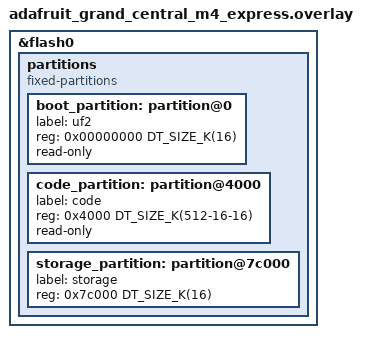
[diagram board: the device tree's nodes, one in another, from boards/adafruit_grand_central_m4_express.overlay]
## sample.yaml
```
sample:
  name: BACnet Smart Actuator (B-SA)

common:
  platform_allow:
    - nucleo_f429zi
    - rpi_pico
    - adafruit_grand_central_m4_express
  build_only: true

tests:

  bacnet-stack.sample.profile.b-sa.bacdl_none:
    tags: bacnet

  bacnet-stack.sample.profile.b-sa.bacdl_mstp:
    extra_configs:
      - CONFIG_BACDL_MSTP=y
    tags: introduction

  bacnet-stack.sample.profile.b-sa.bacdl_bip:
    extra_configs:
      - CONFIG_BACDL_BIP=y
    tags: introduction

  bacnet-stack.sample.profile.b-sa.bacdl_bip6:
    skip: true
    extra_configs:
      - CONFIG_BACDL_BIP6=y
    tags: introduction

  bacnet-stack.sample.profile.b-sa.bacdl_ethernet:
    skip: true
    extra_configs:
      - CONFIG_BACDL_ETHERNET=y
    tags: introduction
```

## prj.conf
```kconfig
# General config
#CONFIG_ASSERT=y
#CONFIG_ASSERT_LEVEL=2
#CONFIG_ASSERT_VERBOSE=y

# Compiler library config
#CONFIG_PICOLIBC=y
#CONFIG_PICOLIBC_USE_MODULE=y
#CONFIG_REQUIRES_FULL_LIBC=y
#CONFIG_MINIMAL_LIBC=y

# system
# some heap is needed for the shell
CONFIG_HEAP_MEM_POOL_SIZE=2048
CONFIG_KERNEL_MEM_POOL=y
CONFIG_MAIN_THREAD_PRIORITY=7
#CONFIG_PICOLIBC=y
CONFIG_ISR_STACK_SIZE=8192
CONFIG_MAIN_STACK_SIZE=8192
CONFIG_IDLE_STACK_SIZE=2048
CONFIG_INIT_STACKS=y

# BACnet Library
CONFIG_BACNETSTACK=y
# BACnet Library - shell
CONFIG_BACNETSTACK_BACNET_SHELL=y
CONFIG_BACNETSTACK_BACNET_BASIC_SHELL=y
CONFIG_BACAPP_PRINT_ENABLED=y
CONFIG_SHELL_STACK_SIZE=16384
# BACnet settings subsystem
CONFIG_BACNETSTACK_BACNET_SETTINGS=y
CONFIG_BACNET_SETTINGS_SHELL=y
# BACnet Library - options
CONFIG_BACNET_MAX_CHARACTER_STRING_BYTES=128
CONFIG_BACAPP_MINIMAL=y
CONFIG_BACAPP_HOST_N_PORT=y
# BACnet Library - objects
CONFIG_BACNET_BASIC_OBJECT_NETWORK_PORT=y
CONFIG_BACNET_BASIC_OBJECT_ANALOG_OUTPUT=y
# BACnet settings subsystem
#CONFIG_BACNETSTACK_BACNET_SETTINGS=y
#CONFIG_BACNET_SETTINGS=y
#CONFIG_BACNET_SETTINGS_SHELL=y
# BACnet Library - server framework
CONFIG_BACNET_BASIC_SERVER=y

# BACnet Datalink Options
CONFIG_BACDL_BIP=y
CONFIG_BACDL_BIP_PORT=47808
# don't define index if you want to use the default interface
# note: with DHCP and AutoIP enabled, index 0=AutoIP, 1=DHCP
# CONFIG_BACDL_BIP_ADDRESS_INDEX=1

# networking
CONFIG_NETWORKING=y
CONFIG_NET_L2_ETHERNET=y
#CONFIG_NET_ARP=y
#CONFIG_NET_TCP=y
CONFIG_NET_UDP=y
CONFIG_NET_SHELL=y
CONFIG_NET_SOCKETS=y
CONFIG_NET_IPV4=y
CONFIG_NET_IPV4_LOG_LEVEL_DBG=n
CONFIG_NET_IF_MAX_IPV4_COUNT=2
CONFIG_NET_IF_UNICAST_IPV4_ADDR_COUNT=2
CONFIG_NET_IF_MCAST_IPV4_ADDR_COUNT=2
# Dynamic IP address
CONFIG_NET_DHCPV4=y
CONFIG_NET_DHCPV4_LOG_LEVEL_DBG=n
CONFIG_NET_IPV4_AUTO=n
CONFIG_NET_IPV4_AUTO_LOG_LEVEL_DBG=n
CONFIG_NET_ICMPV4_LOG_LEVEL_DBG=n
# read the MAC address from settings and set via net_mgmt()
CONFIG_NET_MGMT_EVENT=y
CONFIG_NET_L2_ETHERNET_MGMT=y
CONFIG_NET_CONNECTION_MANAGER=y

# Network debug config
CONFIG_NET_LOG=y
CONFIG_NET_SHELL=y

#CONFIG_DNS_RESOLVER=y
#CONFIG_SLIP_STATISTICS=n

CONFIG_NET_TX_STACK_SIZE=8192
CONFIG_NET_RX_STACK_SIZE=8192

# Enable Shell, Console, and Logging features
CONFIG_CONSOLE=y
CONFIG_PRINTK=y
CONFIG_SHELL=y
CONFIG_KERNEL_SHELL=y
CONFIG_THREAD_MONITOR=y
#CONFIG_BOOT_BANNER=n
CONFIG_THREAD_NAME=y
CONFIG_DEVICE_SHELL=y
#CONFIG_POSIX_CLOCK=y
#CONFIG_DATE_SHELL=y
CONFIG_LOG=y
CONFIG_LOG_BACKEND_UART=y
CONFIG_SHELL_LOG_BACKEND=n
#CONFIG_LOG_STRDUP_BUF_COUNT=4
#CONFIG_LOG_STRDUP_MAX_STRING=96
#CONFIG_NET_CONN_LOG_LEVEL_DEFAULT=n
#CONFIG_NET_CONN_LOG_LEVEL_DBG=y
#CONFIG_NET_IF_LOG_LEVEL_DEFAULT=n
CONFIG_NET_IF_LOG_LEVEL_DBG=n
CONFIG_NET_LOG=y

# enable the thread, stack, and runtime stats
CONFIG_THREAD_ANALYZER=y
CONFIG_THREAD_STACK_INFO=y
CONFIG_THREAD_RUNTIME_STATS=y
#CONFIG_THREAD_RUNTIME_STATS_USE_TIMING_FUNCTIONS=n
#CONFIG_SCHED_THREAD_USAGE=y
#CONFIG_SCHED_THREAD_USAGE_ANALYSIS=y
CONFIG_STATS=y
CONFIG_STATS_SHELL=y

#
# Storage
#
# the dependencies of the SETTINGS option.
CONFIG_FLASH=y
CONFIG_FLASH_MAP=y
#CONFIG_FLASH_PAGE_LAYOUT=y
CONFIG_NVS=y
CONFIG_SETTINGS=y
CONFIG_SETTINGS_NVS=y
CONFIG_SETTINGS_RUNTIME=y
CONFIG_REBOOT=y
#CONFIG_SETTINGS_FILE=y
#CONFIG_SETTINGS_SHELL=y
# native_posix uses a simulated flash
#CONFIG_FLASH_SIMULATOR=y
#CONFIG_DISK_ACCESS=y.
#CONFIG_FILE_SYSTEM=y
#CONFIG_FILE_SYSTEM_LITTLEFS=y
#CONFIG_FILE_SYSTEM_SHELL=y

CONFIG_TEST_RANDOM_GENERATOR=y
CONFIG_TIMER_RANDOM_GENERATOR=y
```

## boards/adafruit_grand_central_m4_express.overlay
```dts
/*
 * Copyright (c) 2020 Google LLC.
 * Copyright (c) 2024 Daikin Comfort Technologies North America, Inc.
 *
 * SPDX-License-Identifier: Apache-2.0
 */
&flash0 {
    partitions {
        compatible = "fixed-partitions";
        #address-cells = <1>;
        #size-cells = <1>;

        boot_partition: partition@0 {
            label = "uf2";
            reg = <0x00000000 DT_SIZE_K(16)>;
            read-only;
        };

        code_partition: partition@4000 {
            label = "code";
            reg = <0x4000 DT_SIZE_K(512-16-16)>;
            read-only;
        };

        /*
         * The final 16 KiB is reserved for the application.
         * Storage partition will be used by FCB/LittleFS/NVS
         * if enabled.
         */
        storage_partition: partition@7c000 {
            label = "storage";
            reg = <0x7c000 DT_SIZE_K(16)>;
        };
    };
};
```

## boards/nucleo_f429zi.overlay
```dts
/*
 * Copyright (c) 2022 STMicroelectronics
 *
 * SPDX-License-Identifier: Apache-2.0
 */
/* FIXME: remove 'delete-node' if building with Zephyr version 4 or later
   when ST removed storage_partition from their SDK board DTS.  */
/delete-node/ &storage_partition;

&flash0 {
  partitions {
    /*
     * nvs subsystem requires 2 sectors with a max total of 32K
     * On F4 series, the only option is to use the following
     * partition, which is compatible with mcuboot usage.
     * (limited by nvs.h: uint16_t sector_size)
     * Located in the first two 16K sectors of the second flash bank
     * (0x100000), above the firmware image which is linked at 0x0 when
     * not using mcuboot. A storage partition overlapping the firmware
     * would make the settings init fail (-EDEADLK) and erasing it would
     * erase the running firmware.
     */
    storage_partition: partition@100000 {
      compatible = "zephyr,mapped-partition";
      label = "storage";
      reg = <0x0100000 DT_SIZE_K(32)>;
    };
  };
};
```

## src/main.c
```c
/**
 * @file
 * @brief BACnet Stack sample Smart Actuator (B-SA) main file
 * @author Steve Karg <skarg@users.sourceforge.net>
 * @date October 2024
 * @copyright SPDX-License-Identifier: Apache-2.0
 */
#include <zephyr/kernel.h>
#include <zephyr/random/random.h>
#include <stdint.h>
#include <stdlib.h>

/* BACnet Stack defines - first */
#include "bacnet/bacdef.h"
/* BACnet Stack core API */
#include "bacnet/version.h"
#include "bacnet/basic/sys/mstimer.h"
/* BACnet Stack basic device API -
   see bacnet/basic/server/bacnet_device.c for details */
#include "bacnet/basic/object/device.h"
/* BACnet Stack basic objects enabled in prj.conf */
#include "bacnet/basic/object/ao.h"
#if (BACNET_PROTOCOL_REVISION >= 17)
#include "bacnet/basic/object/netport.h"
#endif
#include "bacnet/basic/server/bacnet_basic.h"
#include "bacnet/basic/server/bacnet_port.h"
/* BACnet Stack Zephyr services */
#include <bacnet_settings/bacnet_settings.h>
#include <bacnet_osif/bacnet_lock.h>
#include <bacnet_osif/bacnet_reinit.h>
/* Logging module registration is already done in ports/zephyr/main.c */
#include <bacnet_osif/bacnet_log.h>
LOG_MODULE_DECLARE(bacnet, CONFIG_BACNETSTACK_LOG_LEVEL);

/* Default values before we get the device instance and name from settings */
static const uint32_t Device_Instance = 260124;
static const char *Device_Name = "BACnet Smart Actuator (B-SA)";
/* object instances */
static const uint32_t Actuator_Instance = 1;
/* timer for Actuator Update Interval */
static struct mstimer Actuator_Update_Timer;

static void BACnet_Smart_Actuator_Datalink_Init(void)
{
    /* nothing to do */
}

/**
 * @brief Clear any stored BACnet settings before a cold start reboot
 * @param context [in] The context to pass to the callback function
 */
static void BACnet_Smart_Actuator_Coldstart_Callback(void *context)
{
    int err;

    (void)context;
    LOG_INF("COLDSTART: Clearing BACnet settings...");
    err = bacnet_settings_clear();
    if (err < 0) {
        LOG_ERR("COLDSTART: Failed to clear BACnet settings: %d", err);
    } else {
        LOG_INF("COLDSTART: Successfully cleared BACnet settings");
    }
}

/**
 * @brief Callback data for WriteProperty restore iterator
 * @param write_function The WriteProperty function to call
 * @param context The context to pass to the WriteProperty function
 * @return true if the WriteProperty succeeded
 */
static bool
Settings_Restore_Callback(BACNET_WRITE_PROPERTY_DATA *wp_data, void *context)
{
    (void)context;
    return Device_Write_Property(wp_data);
}

/**
 * @brief BACnet Project Initialization Handler
 * @param context [in] The context to pass to the callback function
 * @note This is called from the BACnet task
 */
static void BACnet_Smart_Actuator_Init_Handler(void *context)
{
    (void)context;
    LOG_INF("BACnet Stack Initialized");
    BACnet_Smart_Actuator_Datalink_Init();
    /* initialize objects with default values for this basic sample */
    Device_Init(NULL);
    Device_Set_Object_Instance_Number(Device_Instance);
    Device_Object_Name_ANSI_Init(Device_Name);
    Analog_Output_Create(Actuator_Instance);
    Analog_Output_Name_Set(Actuator_Instance, "Actuator");
    Analog_Output_Units_Set(Actuator_Instance, UNITS_PERCENT);
    Analog_Output_Min_Pres_Value_Set(Actuator_Instance, 0.0f);
    Analog_Output_Max_Pres_Value_Set(Actuator_Instance, 100.0f);
    /* restore any property values previously stored via WriteProperty */
    bacnet_settings_init();
    bacnet_settings_write_property_restore(&Settings_Restore_Callback, NULL);
    /* writable property values are stored with WriteProperty.
       Set this callback after restore to prevent recursion. */
    bacnet_basic_store_callback_set(bacnet_settings_basic_store);
    LOG_INF("BACnet Device ID: %u", Device_Object_Instance_Number());
    /* start the seconds cyclic timer */
    mstimer_set(&Actuator_Update_Timer, 1000);
    bacnet_reinitialize_device_init(CONFIG_BACNET_REINIT_REBOOT_DELAY);
    srand(sys_rand32_get());
}

/**
 * @brief BACnet Project Task Handler
 * @param context [in] The context to pass to the callback function
 * @note This is called from the BACnet task
 */
static void BACnet_Smart_Actuator_Task_Handler(void *context)
{
    float percent = 0.0f, change = 0.0f;

    bacnet_reinitialize_device_task(
        BACnet_Smart_Actuator_Coldstart_Callback, context);
    if (mstimer_expired(&Actuator_Update_Timer)) {
        mstimer_reset(&Actuator_Update_Timer);
        /* simulate an internal software program,
           and update the BACnet object values */
        if (Analog_Output_Out_Of_Service(Actuator_Instance)) {
            return;
        }
        percent = Analog_Output_Present_Value(Actuator_Instance);
        change = -1.0f + 2.0f * ((float)sys_rand32_get() / (float)UINT32_MAX);
        percent += change;
        Analog_Output_Present_Value_Set(
            Actuator_Instance, percent, BACNET_MAX_PRIORITY);
    }
}

int main(void)
{
    bool port_initialized = false;

    LOG_INF("BACnet Device: %s", Device_Name);
    LOG_INF("BACnet Stack Version " BACNET_VERSION_TEXT);
    LOG_INF("BACnet Stack Max APDU: %d", MAX_APDU);
    bacnet_basic_init_callback_set(BACnet_Smart_Actuator_Init_Handler, NULL);
    bacnet_basic_task_callback_set(BACnet_Smart_Actuator_Task_Handler, NULL);
    bacnet_lock();
    bacnet_basic_init();
    bacnet_unlock();
    for (;;) {
        k_sleep(K_MSEC(CONFIG_BACNET_BASIC_SERVER_KSLEEP));
        bacnet_lock();
        bacnet_basic_task();
        if (port_initialized) {
            bacnet_port_task();
        }
        bacnet_unlock();
        /* Port init can wait for an IPv4 address. Keep that wait outside
           the BACnet lock. */
        if (!port_initialized) {
            port_initialized = bacnet_port_init();
        }
    }

    return 0;
}
```
